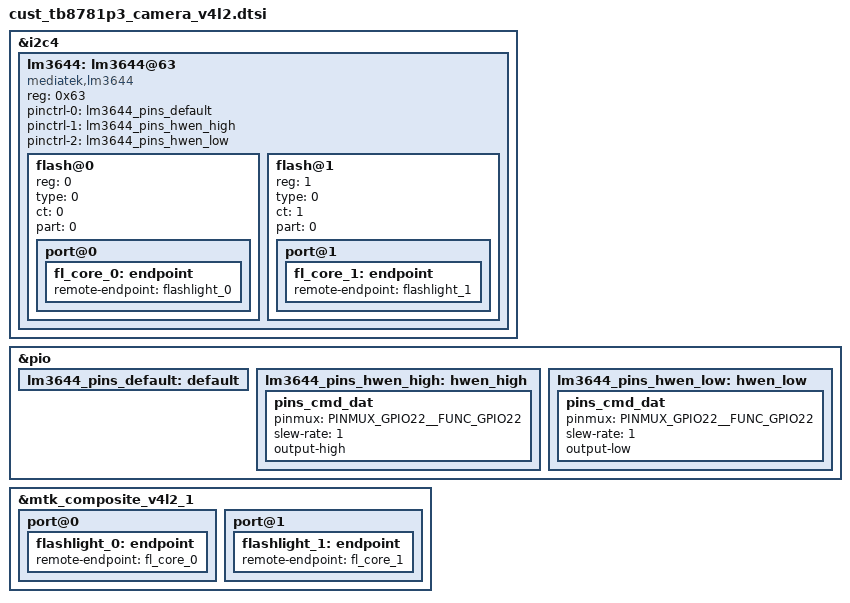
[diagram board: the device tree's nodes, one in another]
// SPDX-License-Identifier: GPL-2.0
/* Copyright (c) 2020 MediaTek Inc. */

&i2c4 {
	lm3644:lm3644@63 {
		compatible = "mediatek,lm3644";
		reg = <0x63>;
		#cooling-cells = <2>;
		pinctrl-names = "default", "hwen_high", "hwen_low";
		pinctrl-0 = <&lm3644_pins_default>;
		pinctrl-1 = <&lm3644_pins_hwen_high>;
		pinctrl-2 = <&lm3644_pins_hwen_low>;
		status = "okay";
		flash@0{
			reg = <0>;
			type = <0>;
			ct = <0>;
			part = <0>;
			port@0 {
				fl_core_0: endpoint {
					remote-endpoint = <&flashlight_0>;
				};
			};
		};
		flash@1{
			reg = <1>;
			type = <0>;
			ct = <1>;
			part = <0>;
			port@1 {
				fl_core_1: endpoint {
					remote-endpoint = <&flashlight_1>;
				};
			};
		};
	};
};

&pio {
	lm3644_pins_default: default {
	};

	lm3644_pins_hwen_high: hwen_high {
		pins_cmd_dat {
			pinmux = <PINMUX_GPIO22__FUNC_GPIO22>;
			slew-rate = <1>;
			output-high;
		};
	};

	lm3644_pins_hwen_low: hwen_low {
		pins_cmd_dat {
			pinmux = <PINMUX_GPIO22__FUNC_GPIO22>;
			slew-rate = <1>;
			output-low;
		};
	};
};

&mtk_composite_v4l2_1 {
	port@0 {
		flashlight_0: endpoint {
			remote-endpoint = <&fl_core_0>;
		};
	};
	port@1 {
		flashlight_1: endpoint {
			remote-endpoint = <&fl_core_1>;
		};
	};
};
